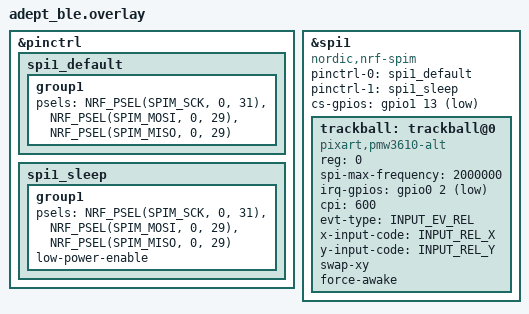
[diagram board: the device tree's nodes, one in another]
/*
 * Adept BLE: PMW3610 trackball.
 *
 * Pin assignment taken from the PCB netlist:
 *   SCLK   E73 pad 9 -> P0.31
 *   SDIO   E73 pad 8 -> P0.29   (bidirectional data)
 *   MOTION E73 pad 7 -> P0.02   (data-ready interrupt)
 *   NCS    E73 pad 6 -> P1.13
 *
 * The sensor has a single bidirectional data line, so SPI MOSI and MISO share
 * P0.29, which is how the reference driver is configured as well.
 *
 * SPDX-License-Identifier: MIT
 */

#include "adept_ble.dtsi"
#include <zephyr/dt-bindings/input/input-event-codes.h>

&pinctrl {
	spi1_default: spi1_default {
		group1 {
			psels = <NRF_PSEL(SPIM_SCK, 0, 31)>,
				<NRF_PSEL(SPIM_MOSI, 0, 29)>,
				<NRF_PSEL(SPIM_MISO, 0, 29)>;
		};
	};

	spi1_sleep: spi1_sleep {
		group1 {
			psels = <NRF_PSEL(SPIM_SCK, 0, 31)>,
				<NRF_PSEL(SPIM_MOSI, 0, 29)>,
				<NRF_PSEL(SPIM_MISO, 0, 29)>;
			low-power-enable;
		};
	};
};

&spi1 {
	status = "okay";
	compatible = "nordic,nrf-spim";
	pinctrl-0 = <&spi1_default>;
	pinctrl-1 = <&spi1_sleep>;
	pinctrl-names = "default", "sleep";

	cs-gpios = <&gpio1 13 GPIO_ACTIVE_LOW>;

	trackball: trackball@0 {
		status = "okay";
		compatible = "pixart,pmw3610-alt";
		reg = <0>;
		spi-max-frequency = <2000000>;
		irq-gpios = <&gpio0 2 (GPIO_ACTIVE_LOW | GPIO_PULL_UP)>;

		/* CPI：每英寸计数，直接决定指针移动速度，范围 200~3200。
		 * 只能按 200 步进取值（200/400/600/800…），因为驱动里是整数除法：
		 *   uint8_t cpi_val = cpi / 200;
		 * 写成 500 不会报错，但 500/200 截断成 2，实际生效的是 400。
		 * 600 是这类轨迹球的常用手感值，想更快改 800，想更慢改 400。 */
		cpi = <600>;
		evt-type = <INPUT_EV_REL>;
		x-input-code = <INPUT_REL_X>;
		y-input-code = <INPUT_REL_Y>;

		/* 传感器在结构上旋转了 90 度安装，坐标需要交换 X/Y。
		 * 当前组合：swap-xy（不额外反转）=> (x, y) -> (y, x)
		 *
		 * 两个轴的方向由这两个属性组合决定，一次只改一个：
		 *   只 swap-xy                => (x, y) -> (y,  x)
		 *   swap-xy + invert-x        => (x, y) -> (y, -x)
		 *   swap-xy + invert-y        => (x, y) -> (-y, x)
		 *   swap-xy + invert-x + invert-y => 整体反向 180 度
		 *   只 invert-x（不 swap）    => (x, y) -> (x, -y)
		 */
		swap-xy;

		/* Keep the sensor in RUN while ZMK is active; it doubles as a
		 * wakeup source.  Remove this if battery life matters more. */
		force-awake;
	};
};
